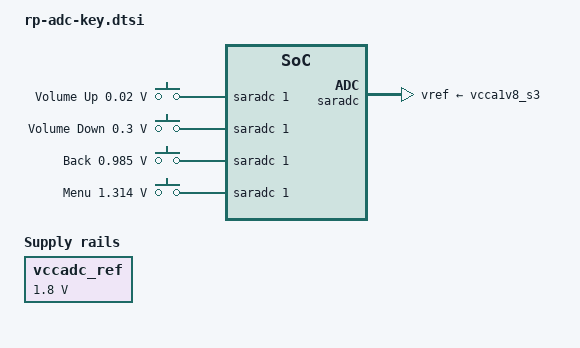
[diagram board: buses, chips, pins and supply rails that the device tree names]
/ {


    vccadc_ref: vccadc-ref {
        compatible = "regulator-fixed";
        regulator-name = "vcc1v8_sys";
        regulator-always-on;
        regulator-boot-on;
        regulator-min-microvolt = <1800000>;
        regulator-max-microvolt = <1800000>;
    };

    adc_keys:adc-keys {
        status = "okay";
        compatible = "adc-keys";
        io-channels = <&saradc 1>;
        io-channel-names = "buttons";
        poll-interval = <100>;
        keyup-threshold-microvolt = <1800000>;

        button-up {
            label = "Volume Up";
            linux,code = <KEY_VOLUMEUP>;
            press-threshold-microvolt = <20000>;
        };

        button-down {
            label = "Volume Down";
            linux,code = <KEY_VOLUMEDOWN>;
            press-threshold-microvolt = <300000>;
        };

        back {
            label = "Back";
            linux,code = <KEY_BACK>;
            press-threshold-microvolt = <985000>;
        };

        menu {
            label = "Menu";
            linux,code = <KEY_MENU>;
            press-threshold-microvolt = <1314000>;
        };
    };
    
};


    
&saradc {
        status = "okay";
        vref-supply = <&vcca1v8_s3>;
    };
